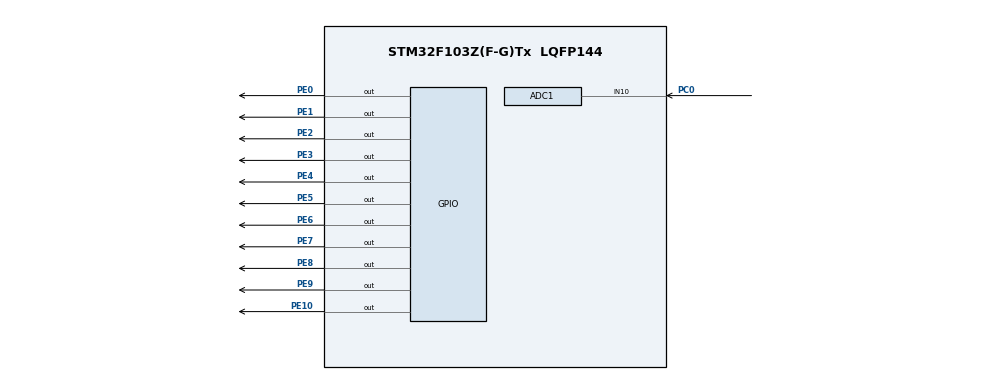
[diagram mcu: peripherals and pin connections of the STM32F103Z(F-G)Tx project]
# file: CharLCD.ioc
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ADC1.Channel-0\#ChannelRegularConversion=ADC_CHANNEL_10
ADC1.NbrOfConversionFlag=1
ADC1.Rank-0\#ChannelRegularConversion=1
ADC1.SamplingTime-0\#ChannelRegularConversion=ADC_SAMPLETIME_1CYCLE_5
ADC1.master=1
Mcu.Family=STM32F1
Mcu.Name=STM32F103Z(F-G)Tx
Mcu.Package=LQFP144
NVIC.PriorityGroup=NVIC_PRIORITYGROUP_4
PA13.Mode=Serial_Wire
PA13.Signal=SYS_JTMS-SWDIO
PA14.Mode=Serial_Wire
PA14.Signal=SYS_JTCK-SWCLK
PC0.Signal=SharedAnalog_PC0
PE0.Signal=GPIO_Output
PE1.Signal=GPIO_Output
PE10.Signal=GPIO_Output
PE2.Signal=GPIO_Output
PE3.Signal=GPIO_Output
PE4.Signal=GPIO_Output
PE5.Signal=GPIO_Output
PE6.Signal=GPIO_Output
PE7.Signal=GPIO_Output
PE8.Signal=GPIO_Output
PE9.Signal=GPIO_Output
ProjectManager.HeapSize=0x200
ProjectManager.StackSize=0x400
ProjectManager.TargetToolchain=MDK-ARM V5.27
RCC.APB1Freq_Value=8000000
RCC.APB2Freq_Value=8000000
SH.SharedAnalog_PC0.0=GPIO_Analog
SH.SharedAnalog_PC0.1=ADC1_IN10,IN10
board=custom

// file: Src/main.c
/* USER CODE BEGIN Header */
/**
  ******************************************************************************
  * @file           : main.c
  * @brief          : Main program body
  ******************************************************************************
  * @attention
  *
  * <h2><center>&copy; Copyright (c) 2019 STMicroelectronics.
  * All rights reserved.</center></h2>
  *
  * This software component is licensed by ST under BSD 3-Clause license,
  * the "License"; You may not use this file except in compliance with the
  * License. You may obtain a copy of the License at:
  *                        opensource.org/licenses/BSD-3-Clause
  *
  ******************************************************************************
  */
/* USER CODE END Header */

#include "main.h"

/* USER CODE BEGIN Includes */
#include "drivers/drv_splc780d1.h"
#include "drivers/dwt_stm32_delay.h"
/* USER CODE END Includes */

ADC_HandleTypeDef hadc1;

/* USER CODE BEGIN PV */
char text[20];
/* USER CODE END PV */

void SystemClock_Config(void);
static void MX_GPIO_Init(void);
static void MX_ADC1_Init(void);

int main(void)
{

  /* MCU Configuration--------------------------------------------------------*/

  /* Reset of all peripherals, Initializes the Flash interface and the Systick. */
  HAL_Init();

  /* Configure the system clock */
  SystemClock_Config();

  /* Initialize all configured peripherals */
  MX_GPIO_Init();
  MX_ADC1_Init();
  /* USER CODE BEGIN 2 */
  // Init for microsecound delay function
  DWT_Delay_Init();

  // Init SPLC780D1 driver
  SPLC780D1_Init(16, 2);
  /* USER CODE END 2 */

  /* Infinite loop */
  /* USER CODE BEGIN WHILE */
  while (1)
  {
  	// Start ADC
  	HAL_ADC_Start(&hadc1);

  	// Polling ADC
  	if (HAL_ADC_PollForConversion(&hadc1, 100) == HAL_OK) {
  		// Make payload
  		sprintf(text, "VR Value: %d", HAL_ADC_GetValue(&hadc1));

  		// Clear display
  		SPLC780D1_Clear();

  		// Draw text to display
  		SPLC780D1_Put(0, 0, text);
  	}

  	// Delay 60ms
  	HAL_Delay(50);
    /* USER CODE END WHILE */

  }
}

void SystemClock_Config(void)
{
  RCC_OscInitTypeDef RCC_OscInitStruct = {0};
  RCC_ClkInitTypeDef RCC_ClkInitStruct = {0};
  RCC_PeriphCLKInitTypeDef PeriphClkInit = {0};

  /** Initializes the CPU, AHB and APB busses clocks
  */
  RCC_OscInitStruct.OscillatorType = RCC_OSCILLATORTYPE_HSI;
  RCC_OscInitStruct.HSIState = RCC_HSI_ON;
  RCC_OscInitStruct.HSICalibrationValue = RCC_HSICALIBRATION_DEFAULT;
  RCC_OscInitStruct.PLL.PLLState = RCC_PLL_NONE;
  if (HAL_RCC_OscConfig(&RCC_OscInitStruct) != HAL_OK)
  {
    Error_Handler();
  }
  /** Initializes the CPU, AHB and APB busses clocks
  */
  RCC_ClkInitStruct.ClockType = RCC_CLOCKTYPE_HCLK|RCC_CLOCKTYPE_SYSCLK
                              |RCC_CLOCKTYPE_PCLK1|RCC_CLOCKTYPE_PCLK2;
  RCC_ClkInitStruct.SYSCLKSource = RCC_SYSCLKSOURCE_HSI;
  RCC_ClkInitStruct.AHBCLKDivider = RCC_SYSCLK_DIV1;
  RCC_ClkInitStruct.APB1CLKDivider = RCC_HCLK_DIV1;
  RCC_ClkInitStruct.APB2CLKDivider = RCC_HCLK_DIV1;

  if (HAL_RCC_ClockConfig(&RCC_ClkInitStruct, FLASH_LATENCY_0) != HAL_OK)
  {
    Error_Handler();
  }
  PeriphClkInit.PeriphClockSelection = RCC_PERIPHCLK_ADC;
  PeriphClkInit.AdcClockSelection = RCC_ADCPCLK2_DIV2;
  if (HAL_RCCEx_PeriphCLKConfig(&PeriphClkInit) != HAL_OK)
  {
    Error_Handler();
  }
}

static void MX_ADC1_Init(void)
{

  ADC_ChannelConfTypeDef sConfig = {0};

  /** Common config
  */
  hadc1.Instance = ADC1;
  hadc1.Init.ScanConvMode = ADC_SCAN_DISABLE;
  hadc1.Init.ContinuousConvMode = DISABLE;
  hadc1.Init.DiscontinuousConvMode = DISABLE;
  hadc1.Init.ExternalTrigConv = ADC_SOFTWARE_START;
  hadc1.Init.DataAlign = ADC_DATAALIGN_RIGHT;
  hadc1.Init.NbrOfConversion = 1;
  if (HAL_ADC_Init(&hadc1) != HAL_OK)
  {
    Error_Handler();
  }
  /** Configure Regular Channel
  */
  sConfig.Channel = ADC_CHANNEL_10;
  sConfig.Rank = ADC_REGULAR_RANK_1;
  sConfig.SamplingTime = ADC_SAMPLETIME_1CYCLE_5;
  if (HAL_ADC_ConfigChannel(&hadc1, &sConfig) != HAL_OK)
  {
    Error_Handler();
  }

}

static void MX_GPIO_Init(void)
{
  GPIO_InitTypeDef GPIO_InitStruct = {0};

  /* GPIO Ports Clock Enable */
  __HAL_RCC_GPIOE_CLK_ENABLE();
  __HAL_RCC_GPIOC_CLK_ENABLE();
  __HAL_RCC_GPIOA_CLK_ENABLE();

  /*Configure GPIO pin Output Level */
  HAL_GPIO_WritePin(GPIOE, GPIO_PIN_2|GPIO_PIN_3|GPIO_PIN_4|GPIO_PIN_5
                          |GPIO_PIN_6|GPIO_PIN_7|GPIO_PIN_8|GPIO_PIN_9
                          |GPIO_PIN_10|GPIO_PIN_0|GPIO_PIN_1, GPIO_PIN_RESET);

  /*Configure GPIO pins : PE2 PE3 PE4 PE5
                           PE6 PE7 PE8 PE9
                           PE10 PE0 PE1 */
  GPIO_InitStruct.Pin = GPIO_PIN_2|GPIO_PIN_3|GPIO_PIN_4|GPIO_PIN_5
                          |GPIO_PIN_6|GPIO_PIN_7|GPIO_PIN_8|GPIO_PIN_9
                          |GPIO_PIN_10|GPIO_PIN_0|GPIO_PIN_1;
  GPIO_InitStruct.Mode = GPIO_MODE_OUTPUT_PP;
  GPIO_InitStruct.Pull = GPIO_NOPULL;
  GPIO_InitStruct.Speed = GPIO_SPEED_FREQ_LOW;
  HAL_GPIO_Init(GPIOE, &GPIO_InitStruct);

  /*Configure GPIO pin : PC0 */
  GPIO_InitStruct.Pin = GPIO_PIN_0;
  GPIO_InitStruct.Mode = GPIO_MODE_ANALOG;
  HAL_GPIO_Init(GPIOC, &GPIO_InitStruct);

}

void Error_Handler(void)
{
}

/************************ (C) COPYRIGHT STMicroelectronics *****END OF FILE****/
